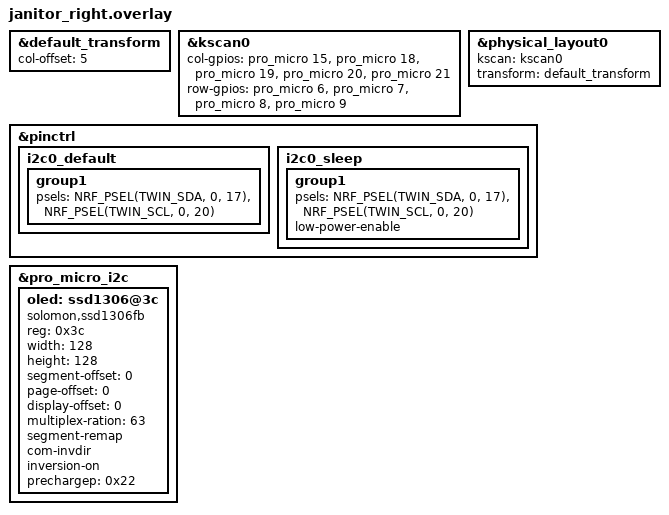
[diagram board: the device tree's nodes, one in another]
#include "janitor.dtsi"

&default_transform {
	col-offset = <5>;
};

&kscan0 {
	col-gpios
		= <&pro_micro 15 GPIO_ACTIVE_HIGH>
		, <&pro_micro 18 GPIO_ACTIVE_HIGH>
		, <&pro_micro 19 GPIO_ACTIVE_HIGH>
		, <&pro_micro 20 GPIO_ACTIVE_HIGH>
		, <&pro_micro 21 GPIO_ACTIVE_HIGH>
		;
	row-gpios
		= <&pro_micro 6 (GPIO_ACTIVE_HIGH | GPIO_PULL_DOWN)>
		, <&pro_micro 7 (GPIO_ACTIVE_HIGH | GPIO_PULL_DOWN)>
		, <&pro_micro 8 (GPIO_ACTIVE_HIGH | GPIO_PULL_DOWN)>
		, <&pro_micro 9 (GPIO_ACTIVE_HIGH | GPIO_PULL_DOWN)>
		;
};

&physical_layout0 {
	kscan = <&kscan0>;
	transform = <&default_transform>;
};

&pinctrl {
	i2c0_default: i2c0_default {
		group1 {
			psels = <NRF_PSEL(TWIN_SDA, 0, 17)>,
				<NRF_PSEL(TWIN_SCL, 0, 20)>;
		};
	};
	i2c0_sleep: i2c0_sleep {
		group1 {
			psels = <NRF_PSEL(TWIN_SDA, 0, 17)>,
				<NRF_PSEL(TWIN_SCL, 0, 20)>;
			low-power-enable;
		};
	};
};

&pro_micro_i2c {
	status = "okay";

	 //TODO: What's the deal with this address
	oled: ssd1306@3c {
		compatible = "solomon,ssd1306fb";
		reg = <0x3c>;
		width = <128>;
		height = <128>;
		segment-offset = <0>;
		page-offset = <0>;
		display-offset = <0>;
		multiplex-ration = <63>;
		segment-remap;
		com-invdir;
		inversion-on;
		prechargep = <0x22>;
	};
};
